# STM32L4R5AGI6 register map
File version: 1.0
Registers are 32-bit, access not given, reset 0x0 unless marked. A register's access mark holds for its fields unless they carry their own. Offsets are from the block's base; [hi:lo] are bit positions; {n}, {i} and the like mark numbered series.

## GFXMMU
Base 0x4002C000
0x00 CR
  [6] 192BM, [31:5] s, [4] AMEIE, [n] B{n}OIE (n=0..3)
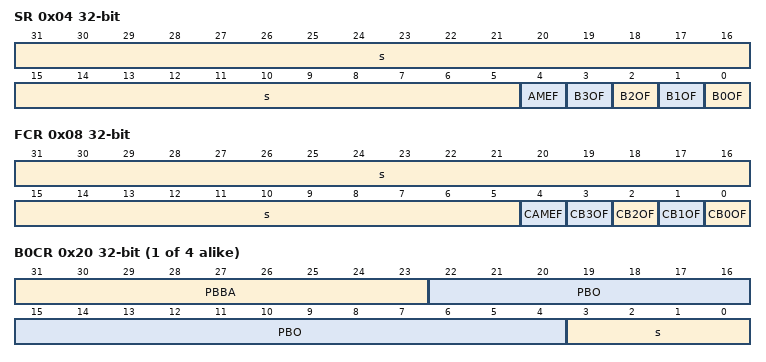
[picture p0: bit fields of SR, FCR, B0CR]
0x04 SR
  [31:5] s, [4] AMEF, [n] B{n}OF (n=0..3)
0x08 FCR
  [31:5] s, [4] CAMEF, [n] CB{n}OF (n=0..3)
0x10 DVR
  [31:0] DV
{0x20+4i} B{i}CR (i=0..3)
  [31:23] PBBA, [22:4] PBO, [3:0] s
0x1000 LUT0L
  [23:16] LVB, [15:8] FVB, [31:1] s, [0] EN
0x1004 LUT0H
  [21:4] LO, [31:0] s
0x2FF8 LUT1023L
  [23:16] LVB, [15:8] FVB, [31:1] s, [0] EN
0x2FFC LUT1023H
  [21:4] LO, [31:0] s

## GPIOA
Base 0x48000000
Same registers: GPIOB 0x48000400, GPIOC 0x48000800, GPIOD 0x48000C00, GPIOE 0x48001000, GPIOF 0x48001400, GPIOG 0x48001800, GPIOH 0x48001C00, GPIOI 0x48002000
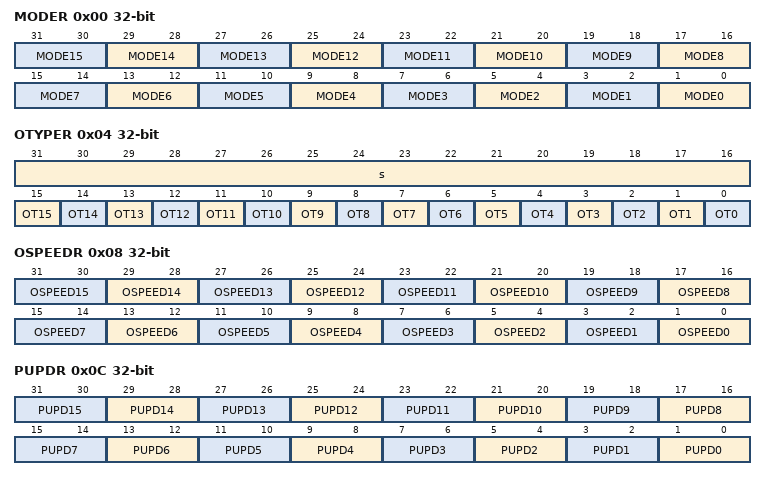
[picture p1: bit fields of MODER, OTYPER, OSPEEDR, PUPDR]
0x00 MODER
  [2n+1:2n] MODE{n} (n=0..15)
0x04 OTYPER
  [31:16] s, [n] OT{n} (n=0..15)
0x08 OSPEEDR
  [2n+1:2n] OSPEED{n} (n=0..15)
0x0C PUPDR
  [2n+1:2n] PUPD{n} (n=0..15)
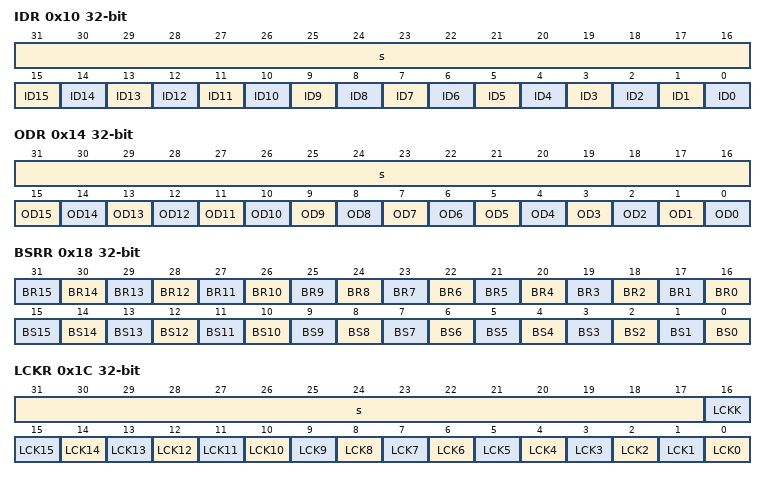
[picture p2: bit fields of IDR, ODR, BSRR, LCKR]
0x10 IDR
  [31:16] s, [n] ID{n} (n=0..15)
0x14 ODR
  [31:16] s, [n] OD{n} (n=0..15)
0x18 BSRR
  [n+16] BR{n} (n=0..15), [n] BS{n} (n=0..15)
0x1C LCKR
  [31:17] s, [16] LCKK, [n] LCK{n} (n=0..15)
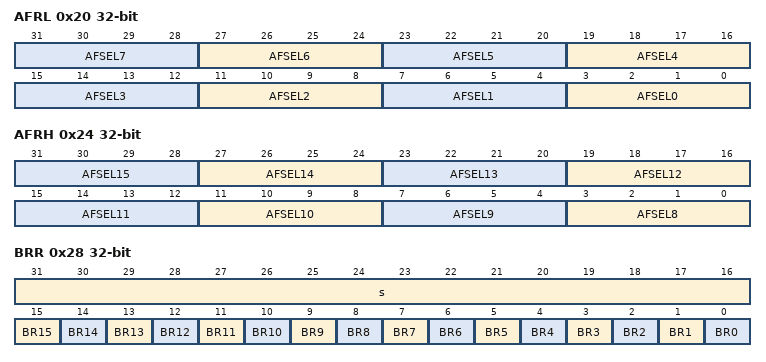
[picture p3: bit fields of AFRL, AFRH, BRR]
0x20 AFRL
  [4n+3:4n] AFSEL{n} (n=0..7)
0x24 AFRH
  [4n-29:4n-32] AFSEL{n} (n=8..15)
0x28 BRR
  [31:16] s, [n] BR{n} (n=0..15)

## ADC
Base 0x50040000
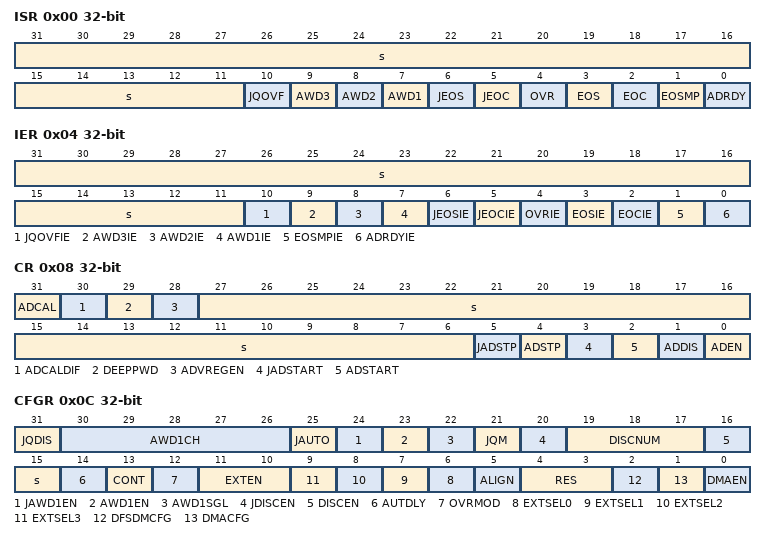
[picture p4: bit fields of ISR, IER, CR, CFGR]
0x00 ISR
  [31:11] s, [10] JQOVF, [9] AWD3, [8] AWD2, [7] AWD1, [6] JEOS, [5] JEOC, [4] OVR, [3] EOS, [2] EOC, [1] EOSMP, [0] ADRDY
0x04 IER
  [31:11] s, [10] JQOVFIE, [9] AWD3IE, [8] AWD2IE, [7] AWD1IE, [6] JEOSIE, [5] JEOCIE, [4] OVRIE, [3] EOSIE, [2] EOCIE, [1] EOSMPIE, [0] ADRDYIE
0x08 CR
  [31] ADCAL, [30] ADCALDIF, [29] DEEPPWD, [28] ADVREGEN, [27:6] s, [5] JADSTP, [4] ADSTP, [3] JADSTART, [2] ADSTART, [1] ADDIS, [0] ADEN
0x0C CFGR
  [31] JQDIS, [30:26] AWD1CH, [25] JAUTO, [24] JAWD1EN, [23] AWD1EN, [22] AWD1SGL, [21] JQM, [20] JDISCEN, [19:17] DISCNUM, [16] DISCEN, [15] s, [14] AUTDLY, [13] CONT, [12] OVRMOD, [11:10] EXTEN, [n+6] EXTSEL{n} (n=0..3), [5] ALIGN, [4:3] RES, [2] DFSDMCFG, [1] DMACFG, [0] DMAEN
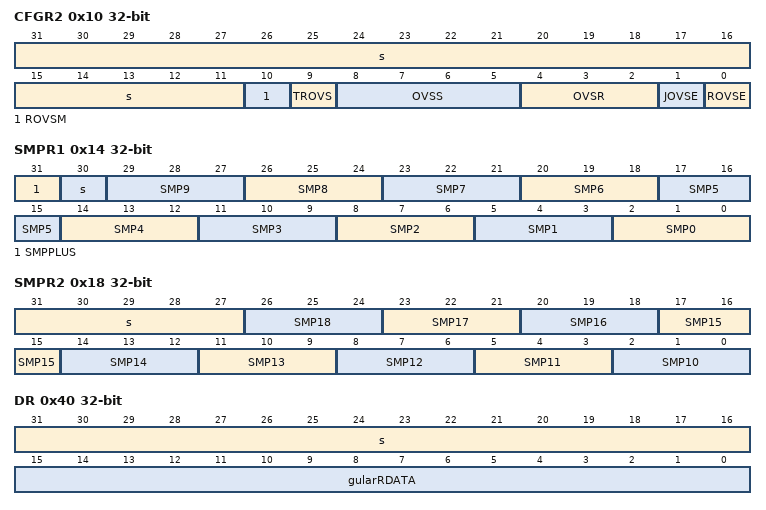
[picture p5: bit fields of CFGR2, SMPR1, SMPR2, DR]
0x10 CFGR2
  [31:11] s, [10] ROVSM, [9] TROVS, [8:5] OVSS, [4:2] OVSR, [1] JOVSE, [0] ROVSE
0x14 SMPR1
  [31] SMPPLUS, [30] s, [3n+2:3n] SMP{n} (n=0..9)
0x18 SMPR2
  [31:27] s, [3n-28:3n-30] SMP{n} (n=10..18)
0x20 TR1
  [27:16] HT1, [31:12] s, [11:0] LT1
0x24 TR2
  [23:16] HT2, [31:8] s, [7:0] LT2
0x28 TR3
  [23:16] HT3, [31:8] s, [7:0] LT3
0x30 SQR1
  [6n+4:6n] SQ{n} (n=1..4), [31:4] s, [3:0] L
0x34 SQR2
  [6n-26:6n-30] SQ{n} (n=5..9), [31:5] s
0x38 SQR3
  [6n-56:6n-60] SQ{n} (n=10..14), [31:5] s
0x3C SQR4
  [10:6] SQ16, [31:5] s, [4:0] SQ15
0x40 DR
  [31:16] s, [15:0] gularRDATA
0x4C JSQR
  [6n+6:6n+2] JSQ{n} (n=1..4), [31:13] s, [7:6] JEXTEN, [5:2] JEXTSEL, [1:0] JL
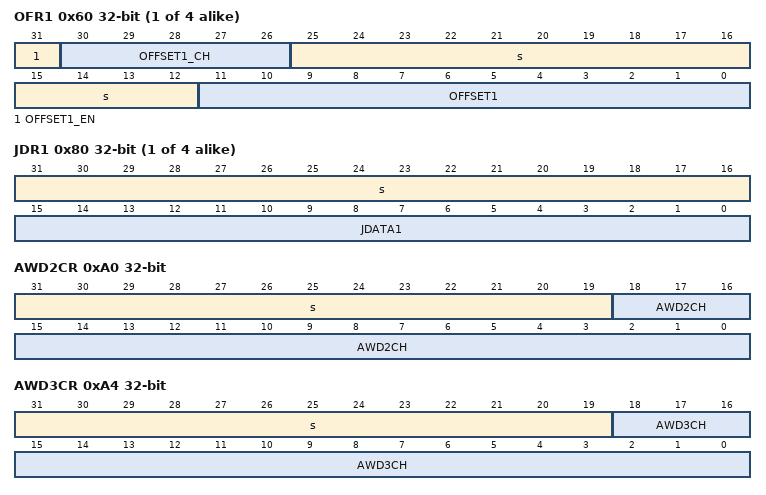
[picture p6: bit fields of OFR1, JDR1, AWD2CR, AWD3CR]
{0x5C+4i} OFR{i} (i=1..4)
  [31] OFFSET{i}_EN, [30:26] OFFSET{i}_CH, [25:12] s, [11:0] OFFSET{i}
{0x7C+4i} JDR{i} (i=1..4)
  [31:16] s, [15:0] JDATA{i}
0xA0 AWD2CR
  [31:19] s, [18:0] AWD2CH
0xA4 AWD3CR
  [31:19] s, [18:0] AWD3CH
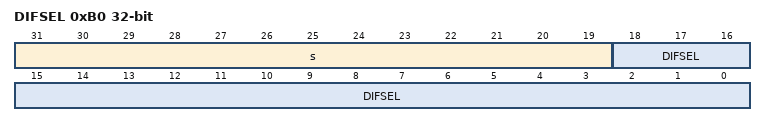
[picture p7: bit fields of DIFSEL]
0xB0 DIFSEL
  [31:19] s, [18:0] DIFSEL
0xB4 CALFACT
  [22:16] CALFACT_D, [31:7] s, [6:0] CALFACT_S

## DCMI
Base 0x50050000
0x00 CR
  [20] OELS, [19] LSM, [18] OEBS, [17:16] BSM, [14] ENABLE, [31:12] s, [11:10] EDM, [9:8] FCRC, [7] VSPOL, [6] HSPOL, [5] PCKPOL, [4] ESS, [3] JPEG, [2] CROP, [1] CM, [0] CAPTURE
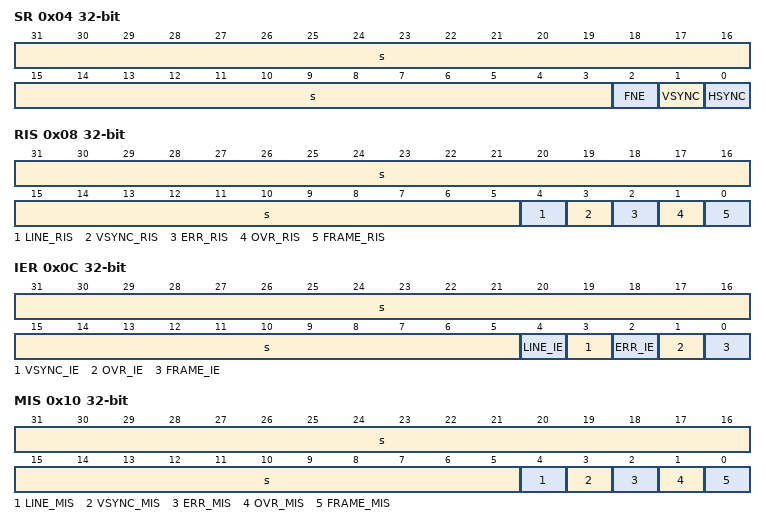
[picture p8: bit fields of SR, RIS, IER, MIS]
0x04 SR
  [31:3] s, [2] FNE, [1] VSYNC, [0] HSYNC
0x08 RIS
  [31:5] s, [4] LINE_RIS, [3] VSYNC_RIS, [2] ERR_RIS, [1] OVR_RIS, [0] FRAME_RIS
0x0C IER
  [31:5] s, [4] LINE_IE, [3] VSYNC_IE, [2] ERR_IE, [1] OVR_IE, [0] FRAME_IE
0x10 MIS
  [31:5] s, [4] LINE_MIS, [3] VSYNC_MIS, [2] ERR_MIS, [1] OVR_MIS, [0] FRAME_MIS
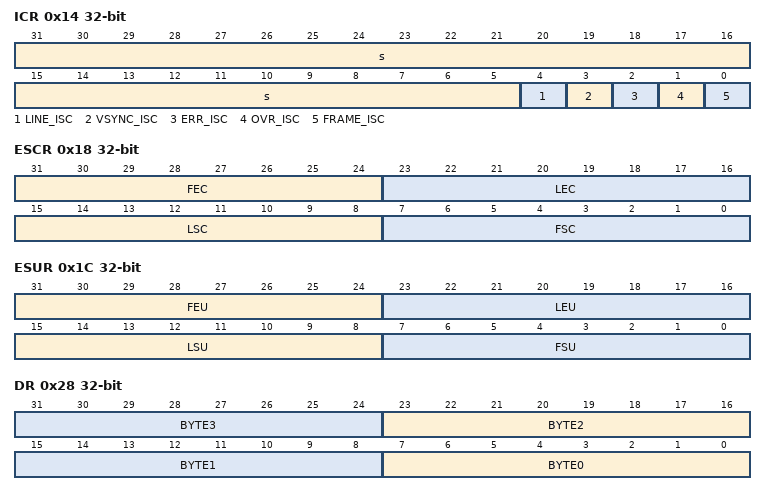
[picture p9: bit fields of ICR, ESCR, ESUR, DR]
0x14 ICR
  [31:5] s, [4] LINE_ISC, [3] VSYNC_ISC, [2] ERR_ISC, [1] OVR_ISC, [0] FRAME_ISC
0x18 ESCR
  [31:24] FEC, [23:16] LEC, [15:8] LSC, [7:0] FSC
0x1C ESUR
  [31:24] FEU, [23:16] LEU, [15:8] LSU, [7:0] FSU
0x20 CWSTRT
  [28:16] VST, [31:14] s, [13:0] HOFFCNT
0x24 CWSIZE
  [29:16] VLINE, [31:14] s, [13:0] CAPCNT
0x28 DR
  [8n+7:8n] BYTE{n} (n=0..3)
